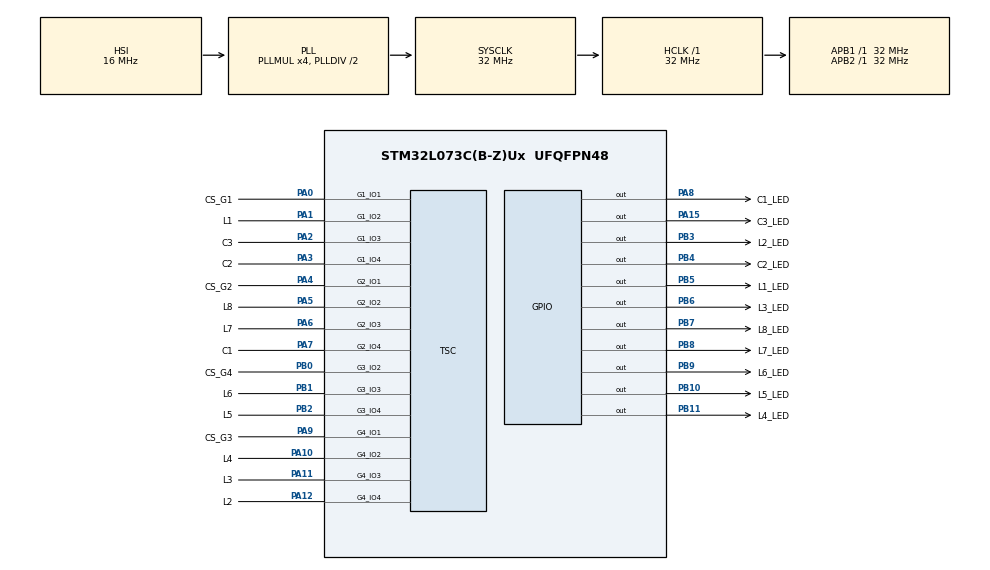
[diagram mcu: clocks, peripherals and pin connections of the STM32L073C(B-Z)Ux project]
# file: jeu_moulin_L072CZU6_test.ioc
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Mcu.Family=STM32L0
Mcu.Name=STM32L073C(B-Z)Ux
Mcu.Package=UFQFPN48
PA0.GPIO_Label=CS_G1
PA0.Mode=G1_IO1-Sampling
PA0.Signal=TSC_G1_IO1
PA1.GPIO_Label=L1
PA1.Mode=G1_IO2-Channel
PA1.Signal=TSC_G1_IO2
PA10.GPIO_Label=L4
PA10.Mode=G4_IO2-Channel
PA10.Signal=TSC_G4_IO2
PA11.GPIO_Label=L3
PA11.Mode=G4_IO3-Channel
PA11.Signal=TSC_G4_IO3
PA12.GPIO_Label=L2
PA12.Mode=G4_IO4-Channel
PA12.Signal=TSC_G4_IO4
PA13.Mode=Serial_Wire
PA13.Signal=SYS_SWDIO
PA14.Mode=Serial_Wire
PA14.Signal=SYS_SWCLK
PA15.GPIO_Label=C3_LED
PA15.Signal=GPIO_Output
PA2.GPIO_Label=C3
PA2.Mode=G1_IO3-Channel
PA2.Signal=TSC_G1_IO3
PA3.GPIO_Label=C2
PA3.Mode=G1_IO4-Channel
PA3.Signal=TSC_G1_IO4
PA4.GPIO_Label=CS_G2
PA4.Mode=G2_IO1-Sampling
PA4.Signal=TSC_G2_IO1
PA5.GPIO_Label=L8
PA5.Mode=G2_IO2-Channel
PA5.Signal=TSC_G2_IO2
PA6.GPIO_Label=L7
PA6.Mode=G2_IO3-Channel
PA6.Signal=TSC_G2_IO3
PA7.GPIO_Label=C1
PA7.Mode=G2_IO4-Channel
PA7.Signal=TSC_G2_IO4
PA8.GPIO_Label=C1_LED
PA8.Signal=GPIO_Output
PA9.GPIO_Label=CS_G3
PA9.Mode=G4_IO1-Sampling
PA9.Signal=TSC_G4_IO1
PB0.GPIO_Label=CS_G4
PB0.Mode=G3_IO2-Sampling
PB0.Signal=TSC_G3_IO2
PB1.GPIO_Label=L6
PB1.Mode=G3_IO3-Channel
PB1.Signal=TSC_G3_IO3
PB10.GPIO_Label=L5_LED
PB10.Signal=GPIO_Output
PB11.GPIO_Label=L4_LED
PB11.Signal=GPIO_Output
PB2.GPIO_Label=L5
PB2.Mode=G3_IO4-Channel
PB2.Signal=TSC_G3_IO4
PB3.GPIO_Label=L2_LED
PB3.Signal=GPIO_Output
PB4.GPIO_Label=C2_LED
PB4.Signal=GPIO_Output
PB5.GPIO_Label=L1_LED
PB5.Signal=GPIO_Output
PB6.GPIO_FM6=I2C_FASTMODEPLUS_PB6
PB6.GPIO_Label=L3_LED
PB6.Signal=GPIO_Output
PB7.GPIO_FM7=I2C_FASTMODEPLUS_PB7
PB7.GPIO_Label=L8_LED
PB7.Signal=GPIO_Output
PB8.GPIO_FM8=I2C_FASTMODEPLUS_PB8
PB8.GPIO_Label=L7_LED
PB8.Signal=GPIO_Output
PB9.GPIO_FM9=I2C_FASTMODEPLUS_PB9
PB9.GPIO_Label=L6_LED
PB9.Signal=GPIO_Output
ProjectManager.HeapSize=0x200
ProjectManager.StackSize=0x400
ProjectManager.TargetToolchain=STM32CubeIDE
RCC.AHBFreq_Value=32000000
RCC.APB1Freq_Value=32000000
RCC.APB1TimFreq_Value=32000000
RCC.APB2Freq_Value=32000000
RCC.APB2TimFreq_Value=32000000
RCC.HCLKFreq_Value=32000000
RCC.HSE_VALUE=8000000
RCC.HSI16_VALUE=16000000
RCC.HSI48_VALUE=48000000
RCC.HSI_VALUE=16000000
RCC.LSE_VALUE=32768
RCC.MSI_VALUE=2097000
RCC.PLLMUL=RCC_PLLMUL_4
RCC.SYSCLKFreq_VALUE=32000000
RCC.SYSCLKSource=RCC_SYSCLKSOURCE_PLLCLK
RCC.VCOOutputFreq_Value=64000000
TOUCHSENSING.IO_TOUCHKEY1=G1_IO2
TOUCHSENSING.IO_TOUCHKEY1-TouchSensing_Enabled=G1_IO2
TOUCHSENSING.IO_TOUCHKEY10=G2_IO4
TOUCHSENSING.IO_TOUCHKEY11=G4_IO4
TOUCHSENSING.IO_TOUCHKEY2=G2_IO2
TOUCHSENSING.IO_TOUCHKEY3=G3_IO3
TOUCHSENSING.IO_TOUCHKEY4=G4_IO2
TOUCHSENSING.IO_TOUCHKEY5=G1_IO3
TOUCHSENSING.IO_TOUCHKEY6=G2_IO3
TOUCHSENSING.IO_TOUCHKEY7=G3_IO4
TOUCHSENSING.IO_TOUCHKEY8=G4_IO3
TOUCHSENSING.IO_TOUCHKEY9=G1_IO4
TOUCHSENSING.TSLPRM_DEBOUNCE_CALIB=20
TOUCHSENSING.TSLPRM_DEBOUNCE_DETECT=4
TOUCHSENSING.TSLPRM_DEBOUNCE_ERROR=20
TOUCHSENSING.TSLPRM_DEBOUNCE_PROX=4
TOUCHSENSING.TSLPRM_DEBOUNCE_RELEASE=4
TOUCHSENSING.TSLPRM_SENSORS_DATAS=TSLPRM_TOTAL_TOUCHKEYS 3 4 4 3 
TOUCHSENSING.TSLPRM_TOTAL_TOUCHKEYS=11
TSC.CTPulseHighLength=TSC_CTPH_4CYCLES
TSC.CTPulseLowLength=TSC_CTPL_4CYCLES
TSC.ChannelIOs-G1_IO2=TSC_GROUP1_IO2
TSC.ChannelIOs-G1_IO3=TSC_GROUP1_IO3
TSC.ChannelIOs-G1_IO4=TSC_GROUP1_IO4
TSC.ChannelIOs-G2_IO2=TSC_GROUP2_IO2
TSC.ChannelIOs-G2_IO3=TSC_GROUP2_IO3
TSC.ChannelIOs-G2_IO4=TSC_GROUP2_IO4
TSC.ChannelIOs-G3_IO3=TSC_GROUP3_IO3
TSC.ChannelIOs-G3_IO4=TSC_GROUP3_IO4
TSC.ChannelIOs-G4_IO2=TSC_GROUP4_IO2
TSC.ChannelIOs-G4_IO3=TSC_GROUP4_IO3
TSC.ChannelIOs-G4_IO4=TSC_GROUP4_IO4
TSC.SamplingIOs-G1_IO1=TSC_GROUP1_IO1
TSC.SamplingIOs-G2_IO1=TSC_GROUP2_IO1
TSC.SamplingIOs-G3_IO2=TSC_GROUP3_IO2
TSC.SamplingIOs-G4_IO1=TSC_GROUP4_IO1
VP_TOUCHSENSING_VS_TOUCHSENSING.Mode=TouchSensing_Enabled
board=custom

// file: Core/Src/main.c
/* USER CODE BEGIN Header */
/**
  ******************************************************************************
  * @file           : main.c
  * @brief          : Main program body
  ******************************************************************************
  * @attention
  *
  * Copyright (c) 2025 STMicroelectronics.
  * All rights reserved.
  *
  * This software is licensed under terms that can be found in the LICENSE file
  * in the root directory of this software component.
  * If no LICENSE file comes with this software, it is provided AS-IS.
  *
  ******************************************************************************
  */
/* USER CODE END Header */
#include "main.h"
#include "touchsensing.h"

/* USER CODE BEGIN PD */
#define TKEY_DET(NB) (MyTKeys[(NB)].p_Data->StateId == TSL_STATEID_DETECT)
#define TKEY_PRX(NB) (MyTKeys[(NB)].p_Data->StateId == TSL_STATEID_PROX)
#define TKEY_REL(NB) (MyTKeys[(NB)].p_Data->StateId == TSL_STATEID_RELEASE)
#define TKEY_CAL(NB) (MyTKeys[(NB)].p_Data->StateId == TSL_STATEID_CALIB)

#define P1 1
#define P2 2
#define P3 3
#define P4 4
#define P5 5
#define P6 6
#define P7 7
#define P8 8
#define P9 9
#define P10 10
#define P11 11
#define P12 12
#define P13 13
#define P14 14
#define P15 15
#define P16 16
#define P17 17
#define P18 18
#define P19 19
#define P20 20
#define P21 21
#define P22 22
#define P23 23
#define P24 24

//define des couleurs
#define RED 1
#define GRN 2
#define OFF 0

//define pour les modes de pins
#define OUTMODE 0x10
#define INMODE 0x20

//define pour les groupe des I/O des LEDs
#define C1_G GPIOA
#define C2_G GPIOB
#define C3_G GPIOA

#define L1_G GPIOB
#define L2_G GPIOB
#define L3_G GPIOB
#define L4_G GPIOB
#define L5_G GPIOB
#define L6_G GPIOB
#define L7_G GPIOB
#define L8_G GPIOB

//define pour les nombre des pins des LEDs
#define C1 8
#define C2 4
#define C3 15

#define L1 5
#define L2 3
#define L3 6
#define L4 11
#define L5 10
#define L6 9
#define L7 8
#define L8 7
/* USER CODE END PD */

TSC_HandleTypeDef htsc;

/* USER CODE BEGIN PV */
tsl_user_status_t tsl_status;
uint16_t i, j;
uint8_t touchDetect[13];	  //correspond aux designateurs du PCB, [0] n'est pas utiliser
uint8_t prevTouchDetect[13];   //correspond à l'ancien état du tableau
uint8_t fieldState[13] = {0}; //correspond aux tableau du terrain contenant les positions
uint8_t touchPressMem[18];    //correspond à la mémoire des touches pressées la case [0] n'est pas utilisé parce que ??
uint8_t memIncrease = 0; 	  //correspond à la variable utile pour monter de cases mémoire
uint8_t btnPressed;			  //correspond à la valeur du bouton pressé de 0 à 11
uint8_t tour = RED;       	  //correspond au tour actuel, sois au rouges, sois au vert
/* USER CODE END PV */

void SystemClock_Config(void);
static void MX_GPIO_Init(void);
static void MX_TSC_Init(void);
/* USER CODE BEGIN PFP */
void LEDP(char IdLed, char color);
void LED_MODE(char pin, GPIO_TypeDef *group, char mode);
void LED_OFF(void);
void LED_Field(uint8_t array[13]);
/* USER CODE END PFP */

int main(void)
{

  /* MCU Configuration--------------------------------------------------------*/

  /* Reset of all peripherals, Initializes the Flash interface and the Systick. */
  HAL_Init();

  /* Configure the system clock */
  SystemClock_Config();

  /* Initialize all configured peripherals */
  MX_GPIO_Init();
  MX_TSC_Init();
  MX_TOUCHSENSING_Init();

  /* Infinite loop */
  /* USER CODE BEGIN WHILE */
  while (1)
  {
		if (tsl_user_Exec_IT() != TSL_USER_STATUS_BUSY) {
			int id;
			for (id = 0; id < TSLPRM_TOTAL_CHANNELS; id++) {
				if (!TKEY_CAL(id)) {
					/*   printf("Sensor%d: Delta %3d Ref %3d Measurement %3d StateId %3d\n"
					 ,id
					 ,MyTKeys[id].p_ChD->Delta
					 ,MyTKeys[id].p_ChD->Ref
					 ,MyTKeys[id].p_ChD->Meas
					 ,MyTKeys[id].p_Data->StateId);*/
					if (TKEY_DET(3) && (TKEY_DET(6))) {
						touchDetect[1] = 1;
					}		//(TKEY_DET(id))// we detect a touch
					else if (TKEY_REL(3) && (TKEY_REL(6))) {
						touchDetect[1] = 0;
					}	//(TKEY_REL(id)) // No more detection

					if (TKEY_DET(3) && (TKEY_DET(7))) {
						touchDetect[2] = 1;
					} else if (TKEY_REL(3) && (TKEY_REL(7))) {
						touchDetect[2] = 0;
					}

					if (TKEY_DET(3) && (TKEY_DET(2))) {
						touchDetect[3] = 1;
					} else if (TKEY_REL(3) && (TKEY_REL(2))) {
						touchDetect[3] = 0;
					}

					if (TKEY_DET(1) && (TKEY_DET(6))) {
						touchDetect[4] = 1;
					} else if (TKEY_REL(1) && (TKEY_REL(6))) {
						touchDetect[4] = 0;
					}

					if (TKEY_DET(1) && (TKEY_DET(7))) {
						touchDetect[5] = 1;
					} else if (TKEY_REL(1) && (TKEY_REL(7))) {
						touchDetect[5] = 0;
					}

					if (TKEY_DET(1) && (TKEY_DET(2))) {
						touchDetect[6] = 1;
					} else if (TKEY_REL(1) && (TKEY_REL(2))) {
						touchDetect[6] = 0;
					}

					if (TKEY_DET(0) && (TKEY_DET(6))) {
						touchDetect[7] = 1;
					} else if (TKEY_REL(0) && (TKEY_REL(6))) {
						touchDetect[7] = 0;
					}

					if (TKEY_DET(0) && (TKEY_DET(7))) {
						touchDetect[8] = 1;
					} else if (TKEY_REL(0) && (TKEY_REL(7))) {
						touchDetect[8] = 0;
					}

					if (TKEY_DET(0) && (TKEY_DET(2))) {
						touchDetect[9] = 1;
					} else if (TKEY_REL(0) && (TKEY_REL(2))) {
						touchDetect[9] = 0;
					}

					if (TKEY_DET(8) && (TKEY_DET(6))) {
						touchDetect[10] = 1;
					} else if (TKEY_REL(8) && (TKEY_REL(6))) {
						touchDetect[10] = 0;
					}

					if (TKEY_DET(8) && (TKEY_DET(7))) {
						touchDetect[11] = 1;
					} else if (TKEY_REL(8) && (TKEY_REL(7))) {
						touchDetect[11] = 0;
					}

					if (TKEY_DET(8) && (TKEY_DET(2))) {
						touchDetect[12] = 1;
					} else if (TKEY_REL(8) && (TKEY_REL(2))) {
						touchDetect[12] = 0;
					}
				}
			}
		} else {
			HAL_Delay(1); //Can be replace by __WFI()
		}
		//début des contrôles pour les LEDs
		//quand la détection est terminée passse dans tous le tableau
		for (int i = 0; i < sizeof(touchDetect); i++) {
			//test si le tableau de fin de détection est le même que celui de l'ancienne détection pour savoir si un flanc a changer d'état
			if (prevTouchDetect[i] == 0 && touchDetect[i] == 1) {
				//flanc détecté
				//test si le tableau à l'addresse i égal 1
				if (touchDetect[i] == 1) {
					//if(btnPressed != i){memIncrease++;}
					btnPressed = i; // Return the index of the first occurrence of 1
				}
					memIncrease++;
					touchPressMem[memIncrease] = btnPressed;
					//of the LED is RED turn it off
					if(fieldState[i] == RED){
						fieldState[btnPressed] = OFF;
					}
					//if it isnt, just change the colour according to the turn
					else{
					fieldState[btnPressed] = tour;
					//progresses the turn
						switch (tour){
						case RED :
							tour = GRN;
							break;
						case GRN :
							tour = RED;
							break;
						case OFF :
							tour = RED;
							break;
						}
					}
				//resets the memory emplacement to 0 when overflow happens
				if(memIncrease >= 18)
				{
					memIncrease = 0;
				}
			}
		prevTouchDetect[i] = touchDetect[i];
		}
		//fonction qui affiche l'état de toutes les position
		LED_Field(fieldState);
    /* USER CODE END WHILE */

  }
}

void SystemClock_Config(void)
{
  RCC_OscInitTypeDef RCC_OscInitStruct = {0};
  RCC_ClkInitTypeDef RCC_ClkInitStruct = {0};

  /** Configure the main internal regulator output voltage
  */
  __HAL_PWR_VOLTAGESCALING_CONFIG(PWR_REGULATOR_VOLTAGE_SCALE1);

  /** Initializes the RCC Oscillators according to the specified parameters
  * in the RCC_OscInitTypeDef structure.
  */
  RCC_OscInitStruct.OscillatorType = RCC_OSCILLATORTYPE_HSI;
  RCC_OscInitStruct.HSIState = RCC_HSI_ON;
  RCC_OscInitStruct.HSICalibrationValue = RCC_HSICALIBRATION_DEFAULT;
  RCC_OscInitStruct.PLL.PLLState = RCC_PLL_ON;
  RCC_OscInitStruct.PLL.PLLSource = RCC_PLLSOURCE_HSI;
  RCC_OscInitStruct.PLL.PLLMUL = RCC_PLLMUL_4;
  RCC_OscInitStruct.PLL.PLLDIV = RCC_PLLDIV_2;
  if (HAL_RCC_OscConfig(&RCC_OscInitStruct) != HAL_OK)
  {
    Error_Handler();
  }

  /** Initializes the CPU, AHB and APB buses clocks
  */
  RCC_ClkInitStruct.ClockType = RCC_CLOCKTYPE_HCLK|RCC_CLOCKTYPE_SYSCLK
                              |RCC_CLOCKTYPE_PCLK1|RCC_CLOCKTYPE_PCLK2;
  RCC_ClkInitStruct.SYSCLKSource = RCC_SYSCLKSOURCE_PLLCLK;
  RCC_ClkInitStruct.AHBCLKDivider = RCC_SYSCLK_DIV1;
  RCC_ClkInitStruct.APB1CLKDivider = RCC_HCLK_DIV1;
  RCC_ClkInitStruct.APB2CLKDivider = RCC_HCLK_DIV1;

  if (HAL_RCC_ClockConfig(&RCC_ClkInitStruct, FLASH_LATENCY_1) != HAL_OK)
  {
    Error_Handler();
  }
}

static void MX_TSC_Init(void)
{

  /** Configure the TSC peripheral
  */
  htsc.Instance = TSC;
  htsc.Init.CTPulseHighLength = TSC_CTPH_4CYCLES;
  htsc.Init.CTPulseLowLength = TSC_CTPL_4CYCLES;
  htsc.Init.SpreadSpectrum = DISABLE;
  htsc.Init.SpreadSpectrumDeviation = 1;
  htsc.Init.SpreadSpectrumPrescaler = TSC_SS_PRESC_DIV1;
  htsc.Init.PulseGeneratorPrescaler = TSC_PG_PRESC_DIV4;
  htsc.Init.MaxCountValue = TSC_MCV_8191;
  htsc.Init.IODefaultMode = TSC_IODEF_OUT_PP_LOW;
  htsc.Init.SynchroPinPolarity = TSC_SYNC_POLARITY_FALLING;
  htsc.Init.AcquisitionMode = TSC_ACQ_MODE_NORMAL;
  htsc.Init.MaxCountInterrupt = DISABLE;
  htsc.Init.ChannelIOs = TSC_GROUP1_IO2|TSC_GROUP1_IO3|TSC_GROUP1_IO4|TSC_GROUP2_IO2
                    |TSC_GROUP2_IO3|TSC_GROUP2_IO4|TSC_GROUP3_IO3|TSC_GROUP3_IO4
                    |TSC_GROUP4_IO2|TSC_GROUP4_IO3|TSC_GROUP4_IO4;
  htsc.Init.ShieldIOs = 0;
  htsc.Init.SamplingIOs = TSC_GROUP1_IO1|TSC_GROUP2_IO1|TSC_GROUP3_IO2|TSC_GROUP4_IO1;
  if (HAL_TSC_Init(&htsc) != HAL_OK)
  {
    Error_Handler();
  }

}

static void MX_GPIO_Init(void)
{
  GPIO_InitTypeDef GPIO_InitStruct = {0};

  /* GPIO Ports Clock Enable */
  __HAL_RCC_GPIOA_CLK_ENABLE();
  __HAL_RCC_GPIOB_CLK_ENABLE();

  /*Configure GPIO pin Output Level */
  HAL_GPIO_WritePin(GPIOB, L5_LED_Pin|L4_LED_Pin|L2_LED_Pin|C2_LED_Pin
                          |L1_LED_Pin|L3_LED_Pin|L8_LED_Pin|L7_LED_Pin
                          |L6_LED_Pin, GPIO_PIN_RESET);

  /*Configure GPIO pin Output Level */
  HAL_GPIO_WritePin(GPIOA, C1_LED_Pin|C3_LED_Pin, GPIO_PIN_RESET);

  /*Configure GPIO pins : L5_LED_Pin L4_LED_Pin L2_LED_Pin C2_LED_Pin
                           L1_LED_Pin L3_LED_Pin L8_LED_Pin L7_LED_Pin
                           L6_LED_Pin */
  GPIO_InitStruct.Pin = L5_LED_Pin|L4_LED_Pin|L2_LED_Pin|C2_LED_Pin
                          |L1_LED_Pin|L3_LED_Pin|L8_LED_Pin|L7_LED_Pin
                          |L6_LED_Pin;
  GPIO_InitStruct.Mode = GPIO_MODE_OUTPUT_PP;
  GPIO_InitStruct.Pull = GPIO_NOPULL;
  GPIO_InitStruct.Speed = GPIO_SPEED_FREQ_LOW;
  HAL_GPIO_Init(GPIOB, &GPIO_InitStruct);

  /*Configure GPIO pins : C1_LED_Pin C3_LED_Pin */
  GPIO_InitStruct.Pin = C1_LED_Pin|C3_LED_Pin;
  GPIO_InitStruct.Mode = GPIO_MODE_OUTPUT_PP;
  GPIO_InitStruct.Pull = GPIO_NOPULL;
  GPIO_InitStruct.Speed = GPIO_SPEED_FREQ_LOW;
  HAL_GPIO_Init(GPIOA, &GPIO_InitStruct);

  /**/
  HAL_I2CEx_EnableFastModePlus(I2C_FASTMODEPLUS_PB6);

  /**/
  HAL_I2CEx_EnableFastModePlus(I2C_FASTMODEPLUS_PB7);

  /**/
  HAL_I2CEx_EnableFastModePlus(I2C_FASTMODEPLUS_PB8);

  /**/
  HAL_I2CEx_EnableFastModePlus(I2C_FASTMODEPLUS_PB9);

}

/* USER CODE BEGIN 4 */
//fonction pour allumer 1 LED
void LEDP(char IdLed, char color) {
	//change toutes les pins de colonne en output
	LED_MODE(C1, C1_G, OUTMODE);
	LED_MODE(C2, C2_G, OUTMODE);
	LED_MODE(C3, C3_G, OUTMODE);

	//la variable IdLed dit quelle led (P1-P16)
	switch (IdLed) {
	//LED1 de la ligne 1
	case P1:
		if (color == RED) {
			//changes les pins pour les colonne qu'on ne souhaite pas allumer en input
			LED_MODE(C1, C1_G, OUTMODE);
			LED_MODE(C2, C2_G, INMODE);
			LED_MODE(C3, C3_G, INMODE);

			//envoie la commande pour la LED qu'on veut allumer
			HAL_GPIO_WritePin(C1_G, C1_LED_Pin, GPIO_PIN_SET);
			HAL_GPIO_WritePin(L1_G, L1_LED_Pin, GPIO_PIN_RESET);

			//set tout les autre pin de ligne à 1 pour ne rien allumer en trop
			HAL_GPIO_WritePin(L2_G, L2_LED_Pin, GPIO_PIN_SET);
			HAL_GPIO_WritePin(L3_G, L3_LED_Pin, GPIO_PIN_SET);
			HAL_GPIO_WritePin(L4_G, L4_LED_Pin, GPIO_PIN_SET);
			HAL_GPIO_WritePin(L5_G, L5_LED_Pin, GPIO_PIN_SET);
			HAL_GPIO_WritePin(L6_G, L6_LED_Pin, GPIO_PIN_SET);
			HAL_GPIO_WritePin(L7_G, L7_LED_Pin, GPIO_PIN_SET);
			HAL_GPIO_WritePin(L8_G, L8_LED_Pin, GPIO_PIN_SET);
		}
		if (color == GRN) {
			//changes les pins pour les colonne qu'on ne souhaite pas allumer en input
			LED_MODE(C1, C1_G, OUTMODE);
			LED_MODE(C2, C2_G, INMODE);
			LED_MODE(C3, C3_G, INMODE);

			//envoie la commande pour la LED qu'on veut allumer
			HAL_GPIO_WritePin(C1_G, C1_LED_Pin, GPIO_PIN_RESET);
			HAL_GPIO_WritePin(L1_G, L1_LED_Pin, GPIO_PIN_SET);

			//set tout les autre pin de ligne à 1 pour ne rien allumer en trop
			HAL_GPIO_WritePin(L2_G, L2_LED_Pin, GPIO_PIN_RESET);
			HAL_GPIO_WritePin(L3_G, L3_LED_Pin, GPIO_PIN_RESET);
			HAL_GPIO_WritePin(L4_G, L4_LED_Pin, GPIO_PIN_RESET);
			HAL_GPIO_WritePin(L5_G, L5_LED_Pin, GPIO_PIN_RESET);
			HAL_GPIO_WritePin(L6_G, L6_LED_Pin, GPIO_PIN_RESET);
			HAL_GPIO_WritePin(L7_G, L7_LED_Pin, GPIO_PIN_RESET);
			HAL_GPIO_WritePin(L8_G, L8_LED_Pin, GPIO_PIN_RESET);
		}
		if (color == OFF) {
			//éteint la LED
			HAL_GPIO_WritePin(C1_G, C1_LED_Pin, GPIO_PIN_RESET);
			HAL_GPIO_WritePin(L1_G, L1_LED_Pin, GPIO_PIN_RESET);
		}
		break;

	//LED2 de la ligne 1
	case P2:
		if (color == RED) {
			//changes les pins pour les colonne qu'on ne souhaite pas allumer en input
			LED_MODE(C1, C1_G, INMODE);
			LED_MODE(C3, C3_G, INMODE);

			//envoie la commande pour la LED qu'on veut allumer
			HAL_GPIO_WritePin(C2_G, C2_LED_Pin, GPIO_PIN_SET);
			HAL_GPIO_WritePin(L1_G, L1_LED_Pin, GPIO_PIN_RESET);

			//set tout les autre pin de ligne à 1 pour ne rien allumer en trop
			HAL_GPIO_WritePin(L2_G, L2_LED_Pin, GPIO_PIN_SET);
			HAL_GPIO_WritePin(L3_G, L3_LED_Pin, GPIO_PIN_SET);
			HAL_GPIO_WritePin(L4_G, L4_LED_Pin, GPIO_PIN_SET);
			HAL_GPIO_WritePin(L5_G, L5_LED_Pin, GPIO_PIN_SET);
			HAL_GPIO_WritePin(L6_G, L6_LED_Pin, GPIO_PIN_SET);
			HAL_GPIO_WritePin(L7_G, L7_LED_Pin, GPIO_PIN_SET);
			HAL_GPIO_WritePin(L8_G, L8_LED_Pin, GPIO_PIN_SET);
		}
		if (color == GRN) {
			//changes les pins pour les colonne qu'on ne souhaite pas allumer en input
			LED_MODE(C1, C1_G, INMODE);
			LED_MODE(C3, C3_G, INMODE);

			//envoie la commande pour la LED qu'on veut allumer
			HAL_GPIO_WritePin(C2_G, C2_LED_Pin, GPIO_PIN_RESET);
			HAL_GPIO_WritePin(L1_G, L1_LED_Pin, GPIO_PIN_SET);

			//set tout les autre pin de ligne à 1 pour ne rien allumer en trop
			HAL_GPIO_WritePin(L2_G, L2_LED_Pin, GPIO_PIN_RESET);
			HAL_GPIO_WritePin(L3_G, L3_LED_Pin, GPIO_PIN_RESET);
			HAL_GPIO_WritePin(L4_G, L4_LED_Pin, GPIO_PIN_RESET);
			HAL_GPIO_WritePin(L5_G, L5_LED_Pin, GPIO_PIN_RESET);
			HAL_GPIO_WritePin(L6_G, L6_LED_Pin, GPIO_PIN_RESET);
			HAL_GPIO_WritePin(L7_G, L7_LED_Pin, GPIO_PIN_RESET);
			HAL_GPIO_WritePin(L8_G, L8_LED_Pin, GPIO_PIN_RESET);
		}
		if (color == OFF) {
			//éteint la LED
			HAL_GPIO_WritePin(C2_G, C2_LED_Pin, GPIO_PIN_RESET);
			HAL_GPIO_WritePin(L1_G, L1_LED_Pin, GPIO_PIN_RESET);
		}
		break;

	//LED3 de la ligne 1
	case P3:
		if (color == RED) {
			//changes les pins pour les colonne qu'on ne souhaite pas allumer en input
			LED_MODE(C1, C1_G, INMODE);
			LED_MODE(C2, C2_G, INMODE);

			//envoie la commande pour la LED qu'on veut allumer
			HAL_GPIO_WritePin(C3_G, C3_LED_Pin, GPIO_PIN_SET);
			HAL_GPIO_WritePin(L1_G, L1_LED_Pin, GPIO_PIN_RESET);

			//set tout les autre pin de ligne à 1 pour ne rien allumer en trop
			HAL_GPIO_WritePin(L2_G, L2_LED_Pin, GPIO_PIN_SET);
			HAL_GPIO_WritePin(L3_G, L3_LED_Pin, GPIO_PIN_SET);
			HAL_GPIO_WritePin(L4_G, L4_LED_Pin, GPIO_PIN_SET);
			HAL_GPIO_WritePin(L5_G, L5_LED_Pin, GPIO_PIN_SET);
			HAL_GPIO_WritePin(L6_G, L6_LED_Pin, GPIO_PIN_SET);
			HAL_GPIO_WritePin(L7_G, L7_LED_Pin, GPIO_PIN_SET);
			HAL_GPIO_WritePin(L8_G, L8_LED_Pin, GPIO_PIN_SET);
		}
		if (color == GRN) {
			//changes les pins pour les colonne qu'on ne souhaite pas allumer en input
			LED_MODE(C1, C1_G, INMODE);
			LED_MODE(C2, C2_G, INMODE);

			//envoie la commande pour la LED qu'on veut allumer
			HAL_GPIO_WritePin(C3_G, C3_LED_Pin, GPIO_PIN_RESET);
			HAL_GPIO_WritePin(L1_G, L1_LED_Pin, GPIO_PIN_SET);

			//set tout les autre pin de ligne à 1 pour ne rien allumer en trop
			HAL_GPIO_WritePin(L2_G, L2_LED_Pin, GPIO_PIN_RESET);
			HAL_GPIO_WritePin(L3_G, L3_LED_Pin, GPIO_PIN_RESET);
			HAL_GPIO_WritePin(L4_G, L4_LED_Pin, GPIO_PIN_RESET);
			HAL_GPIO_WritePin(L5_G, L5_LED_Pin, GPIO_PIN_RESET);
			HAL_GPIO_WritePin(L6_G, L6_LED_Pin, GPIO_PIN_RESET);
			HAL_GPIO_WritePin(L7_G, L7_LED_Pin, GPIO_PIN_RESET);
			HAL_GPIO_WritePin(L8_G, L8_LED_Pin, GPIO_PIN_RESET);
		}
		if (color == OFF) {
			//éteint la LED
			HAL_GPIO_WritePin(C3_G, C3_LED_Pin, GPIO_PIN_RESET);
			HAL_GPIO_WritePin(L1_G, L1_LED_Pin, GPIO_PIN_RESET);
		}
		break;

		//LED1 de la ligne 2
	case P4:
		if (color == RED) {
			//changes les pins pour les colonne qu'on ne souhaite pas allumer en input
			LED_MODE(C2, C2_G, INMODE);
			LED_MODE(C3, C3_G, INMODE);

			//envoie la commande pour la LED qu'on veut allumer
			HAL_GPIO_WritePin(C1_G, C1_LED_Pin, GPIO_PIN_SET);
			HAL_GPIO_WritePin(L2_G, L2_LED_Pin, GPIO_PIN_RESET);

			//set tout les autre pin de ligne à 1 pour ne rien allumer en trop
			HAL_GPIO_WritePin(L1_G, L1_LED_Pin, GPIO_PIN_SET);
			HAL_GPIO_WritePin(L3_G, L3_LED_Pin, GPIO_PIN_SET);
			HAL_GPIO_WritePin(L4_G, L4_LED_Pin, GPIO_PIN_SET);
			HAL_GPIO_WritePin(L5_G, L5_LED_Pin, GPIO_PIN_SET);
			HAL_GPIO_WritePin(L6_G, L6_LED_Pin, GPIO_PIN_SET);
			HAL_GPIO_WritePin(L7_G, L7_LED_Pin, GPIO_PIN_SET);
			HAL_GPIO_WritePin(L8_G, L8_LED_Pin, GPIO_PIN_SET);
		}
		if (color == GRN) {
			//changes les pins pour les colonne qu'on ne souhaite pas allumer en input
			LED_MODE(C2, C2_G, INMODE);
			LED_MODE(C3, C3_G, INMODE);

			//envoie la commande pour la LED qu'on veut allumer
			HAL_GPIO_WritePin(C1_G, C1_LED_Pin, GPIO_PIN_RESET);
			HAL_GPIO_WritePin(L2_G, L2_LED_Pin, GPIO_PIN_SET);

			//set tout les autre pin de ligne à 1 pour ne rien allumer en trop
			HAL_GPIO_WritePin(L1_G, L1_LED_Pin, GPIO_PIN_RESET);
			HAL_GPIO_WritePin(L3_G, L3_LED_Pin, GPIO_PIN_RESET);
			HAL_GPIO_WritePin(L4_G, L4_LED_Pin, GPIO_PIN_RESET);
			HAL_GPIO_WritePin(L5_G, L5_LED_Pin, GPIO_PIN_RESET);
			HAL_GPIO_WritePin(L6_G, L6_LED_Pin, GPIO_PIN_RESET);
			HAL_GPIO_WritePin(L7_G, L7_LED_Pin, GPIO_PIN_RESET);
			HAL_GPIO_WritePin(L8_G, L8_LED_Pin, GPIO_PIN_RESET);
		}
		if (color == OFF) {
			//éteint la LED
			HAL_GPIO_WritePin(C3_G, C3_LED_Pin, GPIO_PIN_RESET);
			HAL_GPIO_WritePin(L2_G, L2_LED_Pin, GPIO_PIN_RESET);
		}
		break;

	//LED2 de la ligne 2
	case P5:
		if (color == RED) {
			//changes les pins pour les colonne qu'on ne souhaite pas allumer en input
			LED_MODE(C1, C1_G, INMODE);
			LED_MODE(C3, C3_G, INMODE);

			//envoie la commande pour la LED qu'on veut allumer
			HAL_GPIO_WritePin(C2_G, C2_LED_Pin, GPIO_PIN_SET);
			HAL_GPIO_WritePin(L2_G, L2_LED_Pin, GPIO_PIN_RESET);

			//set tout les autre pin de ligne à 1 pour ne rien allumer en trop
			HAL_GPIO_WritePin(L1_G, L1_LED_Pin, GPIO_PIN_SET);
			HAL_GPIO_WritePin(L3_G, L3_LED_Pin, GPIO_PIN_SET);
			HAL_GPIO_WritePin(L4_G, L4_LED_Pin, GPIO_PIN_SET);
			HAL_GPIO_WritePin(L5_G, L5_LED_Pin, GPIO_PIN_SET);
			HAL_GPIO_WritePin(L6_G, L6_LED_Pin, GPIO_PIN_SET);
			HAL_GPIO_WritePin(L7_G, L7_LED_Pin, GPIO_PIN_SET);
			HAL_GPIO_WritePin(L8_G, L8_LED_Pin, GPIO_PIN_SET);
		}
		if (color == GRN) {
			//changes les pins pour les colonne qu'on ne souhaite pas allumer en input
			LED_MODE(C1, C1_G, INMODE);
			LED_MODE(C3, C3_G, INMODE);

			//envoie la commande pour la LED qu'on veut allumer
			HAL_GPIO_WritePin(C2_G, C2_LED_Pin, GPIO_PIN_RESET);
			HAL_GPIO_WritePin(L2_G, L2_LED_Pin, GPIO_PIN_SET);

			//set tout les autre pin de ligne à 1 pour ne rien allumer en trop
			HAL_GPIO_WritePin(L1_G, L1_LED_Pin, GPIO_PIN_RESET);
			HAL_GPIO_WritePin(L3_G, L3_LED_Pin, GPIO_PIN_RESET);
			HAL_GPIO_WritePin(L4_G, L4_LED_Pin, GPIO_PIN_RESET);
			HAL_GPIO_WritePin(L5_G, L5_LED_Pin, GPIO_PIN_RESET);
			HAL_GPIO_WritePin(L6_G, L6_LED_Pin, GPIO_PIN_RESET);
			HAL_GPIO_WritePin(L7_G, L7_LED_Pin, GPIO_PIN_RESET);
			HAL_GPIO_WritePin(L8_G, L8_LED_Pin, GPIO_PIN_RESET);
		}
		if (color == OFF) {
			//éteint la LED
			HAL_GPIO_WritePin(C2_G, C2_LED_Pin, GPIO_PIN_RESET);
			HAL_GPIO_WritePin(L2_G, L2_LED_Pin, GPIO_PIN_RESET);
		}
		break;

	//LED3 de la ligne 2
	case P6:
		if (color == RED) {
			//changes les pins pour les colonne qu'on ne souhaite pas allumer en input
			LED_MODE(C1, C1_G, INMODE);
			LED_MODE(C2, C2_G, INMODE);

			//envoie la commande pour la LED qu'on veut allumer
			HAL_GPIO_WritePin(C3_G, C3_LED_Pin, GPIO_PIN_SET);
			HAL_GPIO_WritePin(L2_G, L2_LED_Pin, GPIO_PIN_RESET);

			//set tout les autre pin de ligne à 1 pour ne rien allumer en trop
			HAL_GPIO_WritePin(L1_G, L1_LED_Pin, GPIO_PIN_SET);
			HAL_GPIO_WritePin(L3_G, L3_LED_Pin, GPIO_PIN_SET);
			HAL_GPIO_WritePin(L4_G, L4_LED_Pin, GPIO_PIN_SET);
			HAL_GPIO_WritePin(L5_G, L5_LED_Pin, GPIO_PIN_SET);
			HAL_GPIO_WritePin(L6_G, L6_LED_Pin, GPIO_PIN_SET);
			HAL_GPIO_WritePin(L7_G, L7_LED_Pin, GPIO_PIN_SET);
			HAL_GPIO_WritePin(L8_G, L8_LED_Pin, GPIO_PIN_SET);
		}
		if (color == GRN) {
			//changes les pins pour les colonne qu'on ne souhaite pas allumer en input
			LED_MODE(C1, C1_G, INMODE);
			LED_MODE(C2, C2_G, INMODE);

			//envoie la commande pour la LED qu'on veut allumer
			HAL_GPIO_WritePin(C3_G, C3_LED_Pin, GPIO_PIN_RESET);
			HAL_GPIO_WritePin(L2_G, L2_LED_Pin, GPIO_PIN_SET);

			//set tout les autre pin de ligne à 1 pour ne rien allumer en trop
			HAL_GPIO_WritePin(L1_G, L1_LED_Pin, GPIO_PIN_RESET);
			HAL_GPIO_WritePin(L3_G, L3_LED_Pin, GPIO_PIN_RESET);
			HAL_GPIO_WritePin(L4_G, L4_LED_Pin, GPIO_PIN_RESET);
			HAL_GPIO_WritePin(L5_G, L5_LED_Pin, GPIO_PIN_RESET);
			HAL_GPIO_WritePin(L6_G, L6_LED_Pin, GPIO_PIN_RESET);
			HAL_GPIO_WritePin(L7_G, L7_LED_Pin, GPIO_PIN_RESET);
			HAL_GPIO_WritePin(L8_G, L8_LED_Pin, GPIO_PIN_RESET);
		}
		if (color == OFF) {
			//éteint la LED
			HAL_GPIO_WritePin(C3_G, C3_LED_Pin, GPIO_PIN_RESET);
			HAL_GPIO_WritePin(L2_G, L2_LED_Pin, GPIO_PIN_RESET);
		}
		break;

		//LED1 de la ligne 3
	case P7:
		if (color == RED) {
			//changes les pins pour les colonne qu'on ne souhaite pas allumer en input
			LED_MODE(C2, C2_G, INMODE);
			LED_MODE(C3, C3_G, INMODE);

			//envoie la commande pour la LED qu'on veut allumer
			HAL_GPIO_WritePin(C1_G, C1_LED_Pin, GPIO_PIN_SET);
			HAL_GPIO_WritePin(L3_G, L3_LED_Pin, GPIO_PIN_RESET);

			//set tout les autre pin de ligne à 1 pour ne rien allumer en trop
			HAL_GPIO_WritePin(L1_G, L1_LED_Pin, GPIO_PIN_SET);
			HAL_GPIO_WritePin(L2_G, L2_LED_Pin, GPIO_PIN_SET);
			HAL_GPIO_WritePin(L4_G, L4_LED_Pin, GPIO_PIN_SET);
			HAL_GPIO_WritePin(L5_G, L5_LED_Pin, GPIO_PIN_SET);
			HAL_GPIO_WritePin(L6_G, L6_LED_Pin, GPIO_PIN_SET);
			HAL_GPIO_WritePin(L7_G, L7_LED_Pin, GPIO_PIN_SET);
			HAL_GPIO_WritePin(L8_G, L8_LED_Pin, GPIO_PIN_SET);
		}
		if (color == GRN) {
			//changes les pins pour les colonne qu'on ne souhaite pas allumer en input
			LED_MODE(C2, C2_G, INMODE);
			LED_MODE(C3, C3_G, INMODE);

			//envoie la commande pour la LED qu'on veut allumer
			HAL_GPIO_WritePin(C1_G, C1_LED_Pin, GPIO_PIN_RESET);
			HAL_GPIO_WritePin(L3_G, L3_LED_Pin, GPIO_PIN_SET);

			//set tout les autre pin de ligne à 1 pour ne rien allumer en trop
			HAL_GPIO_WritePin(L1_G, L1_LED_Pin, GPIO_PIN_RESET);
			HAL_GPIO_WritePin(L2_G, L2_LED_Pin, GPIO_PIN_RESET);
			HAL_GPIO_WritePin(L4_G, L4_LED_Pin, GPIO_PIN_RESET);
			HAL_GPIO_WritePin(L5_G, L5_LED_Pin, GPIO_PIN_RESET);
			HAL_GPIO_WritePin(L6_G, L6_LED_Pin, GPIO_PIN_RESET);
			HAL_GPIO_WritePin(L7_G, L7_LED_Pin, GPIO_PIN_RESET);
			HAL_GPIO_WritePin(L8_G, L8_LED_Pin, GPIO_PIN_RESET);
		}
		if (color == OFF) {
			//éteint la LED
			HAL_GPIO_WritePin(C3_G, C3_LED_Pin, GPIO_PIN_RESET);
			HAL_GPIO_WritePin(L3_G, L3_LED_Pin, GPIO_PIN_RESET);
		}
		break;

	//LED2 de la ligne 3
	case P8:
		if (color == RED) {
			//changes les pins pour les colonne qu'on ne souhaite pas allumer en input
			LED_MODE(C1, C1_G, INMODE);
			LED_MODE(C3, C3_G, INMODE);

			//envoie la commande pour la LED qu'on veut allumer
			HAL_GPIO_WritePin(C2_G, C2_LED_Pin, GPIO_PIN_SET);
			HAL_GPIO_WritePin(L3_G, L3_LED_Pin, GPIO_PIN_RESET);

			//set tout les autre pin de ligne à 1 pour ne rien allumer en trop
			HAL_GPIO_WritePin(L1_G, L1_LED_Pin, GPIO_PIN_SET);
			HAL_GPIO_WritePin(L2_G, L2_LED_Pin, GPIO_PIN_SET);
			HAL_GPIO_WritePin(L4_G, L4_LED_Pin, GPIO_PIN_SET);
			HAL_GPIO_WritePin(L5_G, L5_LED_Pin, GPIO_PIN_SET);
			HAL_GPIO_WritePin(L6_G, L6_LED_Pin, GPIO_PIN_SET);
			HAL_GPIO_WritePin(L7_G, L7_LED_Pin, GPIO_PIN_SET);
			HAL_GPIO_WritePin(L8_G, L8_LED_Pin, GPIO_PIN_SET);
		}
		if (color == GRN) {
			//changes les pins pour les colonne qu'on ne souhaite pas allumer en input
			LED_MODE(C1, C1_G, INMODE);
			LED_MODE(C3, C3_G, INMODE);

			//envoie la commande pour la LED qu'on veut allumer
			HAL_GPIO_WritePin(C2_G, C2_LED_Pin, GPIO_PIN_RESET);
			HAL_GPIO_WritePin(L3_G, L3_LED_Pin, GPIO_PIN_SET);

			//set tout les autre pin de ligne à 1 pour ne rien allumer en trop
			HAL_GPIO_WritePin(L1_G, L1_LED_Pin, GPIO_PIN_RESET);
			HAL_GPIO_WritePin(L2_G, L2_LED_Pin, GPIO_PIN_RESET);
			HAL_GPIO_WritePin(L4_G, L4_LED_Pin, GPIO_PIN_RESET);
			HAL_GPIO_WritePin(L5_G, L5_LED_Pin, GPIO_PIN_RESET);
			HAL_GPIO_WritePin(L6_G, L6_LED_Pin, GPIO_PIN_RESET);
			HAL_GPIO_WritePin(L7_G, L7_LED_Pin, GPIO_PIN_RESET);
			HAL_GPIO_WritePin(L8_G, L8_LED_Pin, GPIO_PIN_RESET);
		}
		if (color == OFF) {
			//éteint la LED
			HAL_GPIO_WritePin(C2_G, C2_LED_Pin, GPIO_PIN_RESET);
			HAL_GPIO_WritePin(L3_G, L3_LED_Pin, GPIO_PIN_RESET);
		}
		break;

	//LED3 de la ligne 3
	case P9:
		if (color == RED) {
			//changes les pins pour les colonne qu'on ne souhaite pas allumer en input
			LED_MODE(C1, C1_G, INMODE);
			LED_MODE(C2, C2_G, INMODE);

			//envoie la commande pour la LED qu'on veut allumer
			HAL_GPIO_WritePin(C3_G, C3_LED_Pin, GPIO_PIN_SET);
			HAL_GPIO_WritePin(L3_G, L3_LED_Pin, GPIO_PIN_RESET);

			//set tout les autre pin de ligne à 1 pour ne rien allumer en trop
			HAL_GPIO_WritePin(L1_G, L1_LED_Pin, GPIO_PIN_SET);
			HAL_GPIO_WritePin(L2_G, L2_LED_Pin, GPIO_PIN_SET);
			HAL_GPIO_WritePin(L4_G, L4_LED_Pin, GPIO_PIN_SET);
			HAL_GPIO_WritePin(L5_G, L5_LED_Pin, GPIO_PIN_SET);
			HAL_GPIO_WritePin(L6_G, L6_LED_Pin, GPIO_PIN_SET);
			HAL_GPIO_WritePin(L7_G, L7_LED_Pin, GPIO_PIN_SET);
			HAL_GPIO_WritePin(L8_G, L8_LED_Pin, GPIO_PIN_SET);
		}
		if (color == GRN) {
			//changes les pins pour les colonne qu'on ne souhaite pas allumer en input
			LED_MODE(C1, C1_G, INMODE);
			LED_MODE(C2, C2_G, INMODE);

			//envoie la commande pour la LED qu'on veut allumer
			HAL_GPIO_WritePin(C3_G, C3_LED_Pin, GPIO_PIN_RESET);
			HAL_GPIO_WritePin(L3_G, L3_LED_Pin, GPIO_PIN_SET);

			//set tout les autre pin de ligne à 1 pour ne rien allumer en trop
			HAL_GPIO_WritePin(L1_G, L1_LED_Pin, GPIO_PIN_RESET);
			HAL_GPIO_WritePin(L2_G, L2_LED_Pin, GPIO_PIN_RESET);
			HAL_GPIO_WritePin(L4_G, L4_LED_Pin, GPIO_PIN_RESET);
			HAL_GPIO_WritePin(L5_G, L5_LED_Pin, GPIO_PIN_RESET);
			HAL_GPIO_WritePin(L6_G, L6_LED_Pin, GPIO_PIN_RESET);
			HAL_GPIO_WritePin(L7_G, L7_LED_Pin, GPIO_PIN_RESET);
			HAL_GPIO_WritePin(L8_G, L8_LED_Pin, GPIO_PIN_RESET);
		}
		if (color == OFF) {
			//éteint la LED
			HAL_GPIO_WritePin(C3_G, C3_LED_Pin, GPIO_PIN_RESET);
			HAL_GPIO_WritePin(L3_G, L3_LED_Pin, GPIO_PIN_RESET);
		}
		break;

		//LED1 de la ligne 4
	case P10:
		if (color == RED) {
			//changes les pins pour les colonne qu'on ne souhaite pas allumer en input
			LED_MODE(C2, C2_G, INMODE);
			LED_MODE(C3, C3_G, INMODE);

			//envoie la commande pour la LED qu'on veut allumer
			HAL_GPIO_WritePin(C1_G, C1_LED_Pin, GPIO_PIN_SET);
			HAL_GPIO_WritePin(L4_G, L4_LED_Pin, GPIO_PIN_RESET);

			//set tout les autre pin de ligne à 1 pour ne rien allumer en trop
			HAL_GPIO_WritePin(L1_G, L1_LED_Pin, GPIO_PIN_SET);
			HAL_GPIO_WritePin(L2_G, L2_LED_Pin, GPIO_PIN_SET);
			HAL_GPIO_WritePin(L3_G, L3_LED_Pin, GPIO_PIN_SET);
			HAL_GPIO_WritePin(L5_G, L5_LED_Pin, GPIO_PIN_SET);
			HAL_GPIO_WritePin(L6_G, L6_LED_Pin, GPIO_PIN_SET);
			HAL_GPIO_WritePin(L7_G, L7_LED_Pin, GPIO_PIN_SET);
			HAL_GPIO_WritePin(L8_G, L8_LED_Pin, GPIO_PIN_SET);
		}
		if (color == GRN) {
			//changes les pins pour les colonne qu'on ne souhaite pas allumer en input
			LED_MODE(C2, C2_G, INMODE);
			LED_MODE(C3, C3_G, INMODE);

			//envoie la commande pour la LED qu'on veut allumer
			HAL_GPIO_WritePin(C1_G, C1_LED_Pin, GPIO_PIN_RESET);
			HAL_GPIO_WritePin(L4_G, L4_LED_Pin, GPIO_PIN_SET);

			//set tout les autre pin de ligne à 1 pour ne rien allumer en trop
			HAL_GPIO_WritePin(L1_G, L1_LED_Pin, GPIO_PIN_RESET);
			HAL_GPIO_WritePin(L2_G, L2_LED_Pin, GPIO_PIN_RESET);
			HAL_GPIO_WritePin(L3_G, L3_LED_Pin, GPIO_PIN_RESET);
			HAL_GPIO_WritePin(L5_G, L5_LED_Pin, GPIO_PIN_RESET);
			HAL_GPIO_WritePin(L6_G, L6_LED_Pin, GPIO_PIN_RESET);
			HAL_GPIO_WritePin(L7_G, L7_LED_Pin, GPIO_PIN_RESET);
			HAL_GPIO_WritePin(L8_G, L8_LED_Pin, GPIO_PIN_RESET);
		}
		if (color == OFF) {
			//éteint la LED
			HAL_GPIO_WritePin(C3_G, C3_LED_Pin, GPIO_PIN_RESET);
			HAL_GPIO_WritePin(L4_G, L4_LED_Pin, GPIO_PIN_RESET);
		}
		break;

	//LED2 de la ligne 4
	case P11:
		if (color == RED) {
			//changes les pins pour les colonne qu'on ne souhaite pas allumer en input
			LED_MODE(C1, C1_G, INMODE);
			LED_MODE(C3, C3_G, INMODE);

			//envoie la commande pour la LED qu'on veut allumer
			HAL_GPIO_WritePin(C2_G, C2_LED_Pin, GPIO_PIN_SET);
			HAL_GPIO_WritePin(L4_G, L4_LED_Pin, GPIO_PIN_RESET);

			//set tout les autre pin de ligne à 1 pour ne rien allumer en trop
			HAL_GPIO_WritePin(L1_G, L1_LED_Pin, GPIO_PIN_SET);
			HAL_GPIO_WritePin(L2_G, L2_LED_Pin, GPIO_PIN_SET);
			HAL_GPIO_WritePin(L3_G, L3_LED_Pin, GPIO_PIN_SET);
			HAL_GPIO_WritePin(L5_G, L5_LED_Pin, GPIO_PIN_SET);
			HAL_GPIO_WritePin(L6_G, L6_LED_Pin, GPIO_PIN_SET);
			HAL_GPIO_WritePin(L7_G, L7_LED_Pin, GPIO_PIN_SET);
			HAL_GPIO_WritePin(L8_G, L8_LED_Pin, GPIO_PIN_SET);
		}
		if (color == GRN) {
			//changes les pins pour les colonne qu'on ne souhaite pas allumer en input
			LED_MODE(C1, C1_G, INMODE);
			LED_MODE(C3, C3_G, INMODE);

			//envoie la commande pour la LED qu'on veut allumer
			HAL_GPIO_WritePin(C2_G, C2_LED_Pin, GPIO_PIN_RESET);
			HAL_GPIO_WritePin(L4_G, L4_LED_Pin, GPIO_PIN_SET);

			//set tout les autre pin de ligne à 1 pour ne rien allumer en trop
			HAL_GPIO_WritePin(L1_G, L1_LED_Pin, GPIO_PIN_RESET);
			HAL_GPIO_WritePin(L2_G, L2_LED_Pin, GPIO_PIN_RESET);
			HAL_GPIO_WritePin(L3_G, L3_LED_Pin, GPIO_PIN_RESET);
			HAL_GPIO_WritePin(L5_G, L5_LED_Pin, GPIO_PIN_RESET);
			HAL_GPIO_WritePin(L6_G, L6_LED_Pin, GPIO_PIN_RESET);
			HAL_GPIO_WritePin(L7_G, L7_LED_Pin, GPIO_PIN_RESET);
			HAL_GPIO_WritePin(L8_G, L8_LED_Pin, GPIO_PIN_RESET);
		}
		if (color == OFF) {
			//éteint la LED
			HAL_GPIO_WritePin(C2_G, C2_LED_Pin, GPIO_PIN_RESET);
			HAL_GPIO_WritePin(L4_G, L4_LED_Pin, GPIO_PIN_RESET);
		}
		break;

	//LED3 de la ligne 4
	case P12:
		if (color == RED) {
			//changes les pins pour les colonne qu'on ne souhaite pas allumer en input
			LED_MODE(C1, C1_G, INMODE);
			LED_MODE(C2, C2_G, INMODE);

			//envoie la commande pour la LED qu'on veut allumer
			HAL_GPIO_WritePin(C3_G, C3_LED_Pin, GPIO_PIN_SET);
			HAL_GPIO_WritePin(L4_G, L4_LED_Pin, GPIO_PIN_RESET);

			//set tout les autre pin de ligne à 1 pour ne rien allumer en trop
			HAL_GPIO_WritePin(L1_G, L1_LED_Pin, GPIO_PIN_SET);
			HAL_GPIO_WritePin(L2_G, L2_LED_Pin, GPIO_PIN_SET);
			HAL_GPIO_WritePin(L3_G, L3_LED_Pin, GPIO_PIN_SET);
			HAL_GPIO_WritePin(L5_G, L5_LED_Pin, GPIO_PIN_SET);
			HAL_GPIO_WritePin(L6_G, L6_LED_Pin, GPIO_PIN_SET);
			HAL_GPIO_WritePin(L7_G, L7_LED_Pin, GPIO_PIN_SET);
			HAL_GPIO_WritePin(L8_G, L8_LED_Pin, GPIO_PIN_SET);
		}
		if (color == GRN) {
			//changes les pins pour les colonne qu'on ne souhaite pas allumer en input
			LED_MODE(C1, C1_G, INMODE);
			LED_MODE(C2, C2_G, INMODE);

			//envoie la commande pour la LED qu'on veut allumer
			HAL_GPIO_WritePin(C3_G, C3_LED_Pin, GPIO_PIN_RESET);
			HAL_GPIO_WritePin(L4_G, L4_LED_Pin, GPIO_PIN_SET);

			//set tout les autre pin de ligne à 1 pour ne rien allumer en trop
			HAL_GPIO_WritePin(L1_G, L1_LED_Pin, GPIO_PIN_RESET);
			HAL_GPIO_WritePin(L2_G, L2_LED_Pin, GPIO_PIN_RESET);
			HAL_GPIO_WritePin(L3_G, L3_LED_Pin, GPIO_PIN_RESET);
			HAL_GPIO_WritePin(L5_G, L5_LED_Pin, GPIO_PIN_RESET);
			HAL_GPIO_WritePin(L6_G, L6_LED_Pin, GPIO_PIN_RESET);
			HAL_GPIO_WritePin(L7_G, L7_LED_Pin, GPIO_PIN_RESET);
			HAL_GPIO_WritePin(L8_G, L8_LED_Pin, GPIO_PIN_RESET);
		}
		if (color == OFF) {
			//éteint la LED
			HAL_GPIO_WritePin(C3_G, C3_LED_Pin, GPIO_PIN_RESET);
			HAL_GPIO_WritePin(L4_G, L4_LED_Pin, GPIO_PIN_RESET);
		}
		break;

	//LED1 de la ligne 5
	case P13:
		if (color == RED) {
			//changes les pins pour les colonne qu'on ne souhaite pas allumer en input
			LED_MODE(C2, C2_G, INMODE);
			LED_MODE(C3, C3_G, INMODE);

			//envoie la commande pour la LED qu'on veut allumer
			HAL_GPIO_WritePin(C1_G, C1_LED_Pin, GPIO_PIN_SET);
			HAL_GPIO_WritePin(L5_G, L5_LED_Pin, GPIO_PIN_RESET);

			//set tout les autre pin de ligne à 1 pour ne rien allumer en trop
			HAL_GPIO_WritePin(L1_G, L1_LED_Pin, GPIO_PIN_SET);
			HAL_GPIO_WritePin(L2_G, L2_LED_Pin, GPIO_PIN_SET);
			HAL_GPIO_WritePin(L3_G, L3_LED_Pin, GPIO_PIN_SET);
			HAL_GPIO_WritePin(L4_G, L4_LED_Pin, GPIO_PIN_SET);
			HAL_GPIO_WritePin(L6_G, L6_LED_Pin, GPIO_PIN_SET);
			HAL_GPIO_WritePin(L7_G, L7_LED_Pin, GPIO_PIN_SET);
			HAL_GPIO_WritePin(L8_G, L8_LED_Pin, GPIO_PIN_SET);
		}
		if (color == GRN) {
			//changes les pins pour les colonne qu'on ne souhaite pas allumer en input
			LED_MODE(C2, C2_G, INMODE);
			LED_MODE(C3, C3_G, INMODE);

			//envoie la commande pour la LED qu'on veut allumer
			HAL_GPIO_WritePin(C1_G, C1_LED_Pin, GPIO_PIN_RESET);
			HAL_GPIO_WritePin(L5_G, L5_LED_Pin, GPIO_PIN_SET);

			//set tout les autre pin de ligne à 1 pour ne rien allumer en trop
			HAL_GPIO_WritePin(L1_G, L1_LED_Pin, GPIO_PIN_RESET);
			HAL_GPIO_WritePin(L2_G, L2_LED_Pin, GPIO_PIN_RESET);
			HAL_GPIO_WritePin(L3_G, L3_LED_Pin, GPIO_PIN_RESET);
			HAL_GPIO_WritePin(L4_G, L4_LED_Pin, GPIO_PIN_RESET);
			HAL_GPIO_WritePin(L6_G, L6_LED_Pin, GPIO_PIN_RESET);
			HAL_GPIO_WritePin(L7_G, L7_LED_Pin, GPIO_PIN_RESET);
			HAL_GPIO_WritePin(L8_G, L8_LED_Pin, GPIO_PIN_RESET);
		}
		if (color == OFF) {
			//éteint la LED
			HAL_GPIO_WritePin(C1_G, C1_LED_Pin, GPIO_PIN_RESET);
			HAL_GPIO_WritePin(L5_G, L5_LED_Pin, GPIO_PIN_RESET);
		}
		break;

	//LED2 de la ligne 5
	case P14:
		if (color == RED) {
			//changes les pins pour les colonne qu'on ne souhaite pas allumer en input
			LED_MODE(C1, C1_G, INMODE);
			LED_MODE(C3, C3_G, INMODE);

			//envoie la commande pour la LED qu'on veut allumer
			HAL_GPIO_WritePin(C2_G, C2_LED_Pin, GPIO_PIN_SET);
			HAL_GPIO_WritePin(L5_G, L5_LED_Pin, GPIO_PIN_RESET);

			//set tout les autre pin de ligne à 1 pour ne rien allumer en trop
			HAL_GPIO_WritePin(L1_G, L1_LED_Pin, GPIO_PIN_SET);
			HAL_GPIO_WritePin(L2_G, L2_LED_Pin, GPIO_PIN_SET);
			HAL_GPIO_WritePin(L3_G, L3_LED_Pin, GPIO_PIN_SET);
			HAL_GPIO_WritePin(L4_G, L4_LED_Pin, GPIO_PIN_SET);
			HAL_GPIO_WritePin(L6_G, L6_LED_Pin, GPIO_PIN_SET);
			HAL_GPIO_WritePin(L7_G, L7_LED_Pin, GPIO_PIN_SET);
			HAL_GPIO_WritePin(L8_G, L8_LED_Pin, GPIO_PIN_SET);
		}
		if (color == GRN) {
			//changes les pins pour les colonne qu'on ne souhaite pas allumer en input
			LED_MODE(C1, C1_G, INMODE);
			LED_MODE(C3, C3_G, INMODE);

			//envoie la commande pour la LED qu'on veut allumer
			HAL_GPIO_WritePin(C2_G, C2_LED_Pin, GPIO_PIN_RESET);
			HAL_GPIO_WritePin(L5_G, L5_LED_Pin, GPIO_PIN_SET);

			//set tout les autre pin de ligne à 1 pour ne rien allumer en trop
			HAL_GPIO_WritePin(L1_G, L1_LED_Pin, GPIO_PIN_RESET);
			HAL_GPIO_WritePin(L2_G, L2_LED_Pin, GPIO_PIN_RESET);
			HAL_GPIO_WritePin(L3_G, L3_LED_Pin, GPIO_PIN_RESET);
			HAL_GPIO_WritePin(L4_G, L4_LED_Pin, GPIO_PIN_RESET);
			HAL_GPIO_WritePin(L6_G, L6_LED_Pin, GPIO_PIN_RESET);
			HAL_GPIO_WritePin(L7_G, L7_LED_Pin, GPIO_PIN_RESET);
			HAL_GPIO_WritePin(L8_G, L8_LED_Pin, GPIO_PIN_RESET);
		}
		if (color == OFF) {
			//éteint la LED
			HAL_GPIO_WritePin(C2_G, C2_LED_Pin, GPIO_PIN_RESET);
			HAL_GPIO_WritePin(L5_G, L5_LED_Pin, GPIO_PIN_RESET);
		}
		break;

	//LED3 de la ligne 5
	case P15:
		if (color == RED) {
			//changes les pins pour les colonne qu'on ne souhaite pas allumer en input
			LED_MODE(C1, C1_G, INMODE);
			LED_MODE(C2, C2_G, INMODE);

			//envoie la commande pour la LED qu'on veut allumer
			HAL_GPIO_WritePin(C3_G, C3_LED_Pin, GPIO_PIN_SET);
			HAL_GPIO_WritePin(L5_G, L5_LED_Pin, GPIO_PIN_RESET);

			//set tout les autre pin de ligne à 1 pour ne rien allumer en trop
			HAL_GPIO_WritePin(L1_G, L1_LED_Pin, GPIO_PIN_SET);
			HAL_GPIO_WritePin(L2_G, L2_LED_Pin, GPIO_PIN_SET);
			HAL_GPIO_WritePin(L3_G, L3_LED_Pin, GPIO_PIN_SET);
			HAL_GPIO_WritePin(L5_G, L4_LED_Pin, GPIO_PIN_SET);
			HAL_GPIO_WritePin(L6_G, L6_LED_Pin, GPIO_PIN_SET);
			HAL_GPIO_WritePin(L7_G, L7_LED_Pin, GPIO_PIN_SET);
			HAL_GPIO_WritePin(L8_G, L8_LED_Pin, GPIO_PIN_SET);
		}
		if (color == GRN) {
			//changes les pins pour les colonne qu'on ne souhaite pas allumer en input
			LED_MODE(C1, C1_G, INMODE);
			LED_MODE(C2, C2_G, INMODE);

			//envoie la commande pour la LED qu'on veut allumer
			HAL_GPIO_WritePin(C3_G, C3_LED_Pin, GPIO_PIN_RESET);
			HAL_GPIO_WritePin(L5_G, L5_LED_Pin, GPIO_PIN_SET);

			//set tout les autre pin de ligne à 1 pour ne rien allumer en trop
			HAL_GPIO_WritePin(L1_G, L1_LED_Pin, GPIO_PIN_RESET);
			HAL_GPIO_WritePin(L2_G, L2_LED_Pin, GPIO_PIN_RESET);
			HAL_GPIO_WritePin(L3_G, L3_LED_Pin, GPIO_PIN_RESET);
			HAL_GPIO_WritePin(L4_G, L4_LED_Pin, GPIO_PIN_RESET);
			HAL_GPIO_WritePin(L6_G, L6_LED_Pin, GPIO_PIN_RESET);
			HAL_GPIO_WritePin(L7_G, L7_LED_Pin, GPIO_PIN_RESET);
			HAL_GPIO_WritePin(L8_G, L8_LED_Pin, GPIO_PIN_RESET);
		}
		if (color == OFF) {
			//éteint la LED
			HAL_GPIO_WritePin(C3_G, C3_LED_Pin, GPIO_PIN_RESET);
			HAL_GPIO_WritePin(L5_G, L5_LED_Pin, GPIO_PIN_RESET);
		}
		break;
		//LED1 de la ligne 6
	case P16:
		if (color == RED) {
			//changes les pins pour les colonne qu'on ne souhaite pas allumer en input
			LED_MODE(C2, C2_G, INMODE);
			LED_MODE(C3, C3_G, INMODE);

			//envoie la commande pour la LED qu'on veut allumer
			HAL_GPIO_WritePin(C1_G, C1_LED_Pin, GPIO_PIN_SET);
			HAL_GPIO_WritePin(L6_G, L6_LED_Pin, GPIO_PIN_RESET);

			//set tout les autre pin de ligne à 1 pour ne rien allumer en trop
			HAL_GPIO_WritePin(L1_G, L1_LED_Pin, GPIO_PIN_SET);
			HAL_GPIO_WritePin(L3_G, L3_LED_Pin, GPIO_PIN_SET);
			HAL_GPIO_WritePin(L4_G, L4_LED_Pin, GPIO_PIN_SET);
			HAL_GPIO_WritePin(L5_G, L5_LED_Pin, GPIO_PIN_SET);
			HAL_GPIO_WritePin(L2_G, L2_LED_Pin, GPIO_PIN_SET);
			HAL_GPIO_WritePin(L7_G, L7_LED_Pin, GPIO_PIN_SET);
			HAL_GPIO_WritePin(L8_G, L8_LED_Pin, GPIO_PIN_SET);
		}
		if (color == GRN) {
			//changes les pins pour les colonne qu'on ne souhaite pas allumer en input
			LED_MODE(C2, C2_G, INMODE);
			LED_MODE(C3, C3_G, INMODE);

			//envoie la commande pour la LED qu'on veut allumer
			HAL_GPIO_WritePin(C1_G, C1_LED_Pin, GPIO_PIN_RESET);
			HAL_GPIO_WritePin(L6_G, L6_LED_Pin, GPIO_PIN_SET);

			//set tout les autre pin de ligne à 1 pour ne rien allumer en trop
			HAL_GPIO_WritePin(L1_G, L1_LED_Pin, GPIO_PIN_RESET);
			HAL_GPIO_WritePin(L3_G, L3_LED_Pin, GPIO_PIN_RESET);
			HAL_GPIO_WritePin(L4_G, L4_LED_Pin, GPIO_PIN_RESET);
			HAL_GPIO_WritePin(L5_G, L5_LED_Pin, GPIO_PIN_RESET);
			HAL_GPIO_WritePin(L2_G, L2_LED_Pin, GPIO_PIN_RESET);
			HAL_GPIO_WritePin(L7_G, L7_LED_Pin, GPIO_PIN_RESET);
			HAL_GPIO_WritePin(L8_G, L8_LED_Pin, GPIO_PIN_RESET);
		}
		if (color == OFF) {
			//éteint la LED
			HAL_GPIO_WritePin(C1_G, C1_LED_Pin, GPIO_PIN_RESET);
			HAL_GPIO_WritePin(L6_G, L6_LED_Pin, GPIO_PIN_RESET);
		}
		break;

	//LED2 de la ligne 6
	case P17:
		if (color == RED) {
			//changes les pins pour les colonne qu'on ne souhaite pas allumer en input
			LED_MODE(C1, C1_G, INMODE);
			LED_MODE(C3, C3_G, INMODE);

			//envoie la commande pour la LED qu'on veut allumer
			HAL_GPIO_WritePin(C2_G, C2_LED_Pin, GPIO_PIN_SET);
			HAL_GPIO_WritePin(L6_G, L6_LED_Pin, GPIO_PIN_RESET);

			//set tout les autre pin de ligne à 1 pour ne rien allumer en trop
			HAL_GPIO_WritePin(L1_G, L1_LED_Pin, GPIO_PIN_SET);
			HAL_GPIO_WritePin(L3_G, L3_LED_Pin, GPIO_PIN_SET);
			HAL_GPIO_WritePin(L4_G, L4_LED_Pin, GPIO_PIN_SET);
			HAL_GPIO_WritePin(L5_G, L5_LED_Pin, GPIO_PIN_SET);
			HAL_GPIO_WritePin(L2_G, L2_LED_Pin, GPIO_PIN_SET);
			HAL_GPIO_WritePin(L7_G, L7_LED_Pin, GPIO_PIN_SET);
			HAL_GPIO_WritePin(L8_G, L8_LED_Pin, GPIO_PIN_SET);
		}
		if (color == GRN) {
			//changes les pins pour les colonne qu'on ne souhaite pas allumer en input
			LED_MODE(C1, C1_G, INMODE);
			LED_MODE(C3, C3_G, INMODE);

			//envoie la commande pour la LED qu'on veut allumer
			HAL_GPIO_WritePin(C2_G, C2_LED_Pin, GPIO_PIN_RESET);
			HAL_GPIO_WritePin(L6_G, L6_LED_Pin, GPIO_PIN_SET);

			//set tout les autre pin de ligne à 1 pour ne rien allumer en trop
			HAL_GPIO_WritePin(L1_G, L1_LED_Pin, GPIO_PIN_RESET);
			HAL_GPIO_WritePin(L3_G, L3_LED_Pin, GPIO_PIN_RESET);
			HAL_GPIO_WritePin(L4_G, L4_LED_Pin, GPIO_PIN_RESET);
			HAL_GPIO_WritePin(L5_G, L5_LED_Pin, GPIO_PIN_RESET);
			HAL_GPIO_WritePin(L2_G, L2_LED_Pin, GPIO_PIN_RESET);
			HAL_GPIO_WritePin(L7_G, L7_LED_Pin, GPIO_PIN_RESET);
			HAL_GPIO_WritePin(L8_G, L8_LED_Pin, GPIO_PIN_RESET);
		}
		if (color == OFF) {
			//éteint la LED
			HAL_GPIO_WritePin(C2_G, C2_LED_Pin, GPIO_PIN_RESET);
			HAL_GPIO_WritePin(L6_G, L6_LED_Pin, GPIO_PIN_RESET);
		}
		break;

	//LED3 de la ligne 6
	case P18:
		if (color == RED) {
			//changes les pins pour les colonne qu'on ne souhaite pas allumer en input
			LED_MODE(C1, C1_G, INMODE);
			LED_MODE(C2, C2_G, INMODE);

			//envoie la commande pour la LED qu'on veut allumer
			HAL_GPIO_WritePin(C3_G, C3_LED_Pin, GPIO_PIN_SET);
			HAL_GPIO_WritePin(L6_G, L6_LED_Pin, GPIO_PIN_RESET);

			//set tout les autre pin de ligne à 1 pour ne rien allumer en trop
			HAL_GPIO_WritePin(L1_G, L1_LED_Pin, GPIO_PIN_SET);
			HAL_GPIO_WritePin(L3_G, L3_LED_Pin, GPIO_PIN_SET);
			HAL_GPIO_WritePin(L4_G, L4_LED_Pin, GPIO_PIN_SET);
			HAL_GPIO_WritePin(L5_G, L5_LED_Pin, GPIO_PIN_SET);
			HAL_GPIO_WritePin(L2_G, L2_LED_Pin, GPIO_PIN_SET);
			HAL_GPIO_WritePin(L7_G, L7_LED_Pin, GPIO_PIN_SET);
			HAL_GPIO_WritePin(L8_G, L8_LED_Pin, GPIO_PIN_SET);
		}
		if (color == GRN) {
			//changes les pins pour les colonne qu'on ne souhaite pas allumer en input
			LED_MODE(C1, C1_G, INMODE);
			LED_MODE(C2, C2_G, INMODE);

			//envoie la commande pour la LED qu'on veut allumer
			HAL_GPIO_WritePin(C3_G, C3_LED_Pin, GPIO_PIN_RESET);
			HAL_GPIO_WritePin(L6_G, L6_LED_Pin, GPIO_PIN_SET);

			//set tout les autre pin de ligne à 1 pour ne rien allumer en trop
			HAL_GPIO_WritePin(L1_G, L1_LED_Pin, GPIO_PIN_RESET);
			HAL_GPIO_WritePin(L3_G, L3_LED_Pin, GPIO_PIN_RESET);
			HAL_GPIO_WritePin(L4_G, L4_LED_Pin, GPIO_PIN_RESET);
			HAL_GPIO_WritePin(L5_G, L5_LED_Pin, GPIO_PIN_RESET);
			HAL_GPIO_WritePin(L2_G, L2_LED_Pin, GPIO_PIN_RESET);
			HAL_GPIO_WritePin(L7_G, L7_LED_Pin, GPIO_PIN_RESET);
			HAL_GPIO_WritePin(L8_G, L8_LED_Pin, GPIO_PIN_RESET);
		}
		if (color == OFF) {
			//éteint la LED
			HAL_GPIO_WritePin(C3_G, C3_LED_Pin, GPIO_PIN_RESET);
			HAL_GPIO_WritePin(L6_G, L6_LED_Pin, GPIO_PIN_RESET);
		}
		break;

		//LED1 de la ligne 7
	case P19:
		if (color == RED) {
			//changes les pins pour les colonne qu'on ne souhaite pas allumer en input
			LED_MODE(C2, C2_G, INMODE);
			LED_MODE(C3, C3_G, INMODE);

			//envoie la commande pour la LED qu'on veut allumer
			HAL_GPIO_WritePin(C1_G, C1_LED_Pin, GPIO_PIN_SET);
			HAL_GPIO_WritePin(L7_G, L7_LED_Pin, GPIO_PIN_RESET);

			//set tout les autre pin de ligne à 1 pour ne rien allumer en trop
			HAL_GPIO_WritePin(L1_G, L1_LED_Pin, GPIO_PIN_SET);
			HAL_GPIO_WritePin(L2_G, L2_LED_Pin, GPIO_PIN_SET);
			HAL_GPIO_WritePin(L4_G, L4_LED_Pin, GPIO_PIN_SET);
			HAL_GPIO_WritePin(L5_G, L5_LED_Pin, GPIO_PIN_SET);
			HAL_GPIO_WritePin(L6_G, L6_LED_Pin, GPIO_PIN_SET);
			HAL_GPIO_WritePin(L3_G, L3_LED_Pin, GPIO_PIN_SET);
			HAL_GPIO_WritePin(L8_G, L8_LED_Pin, GPIO_PIN_SET);
		}
		if (color == GRN) {
			//changes les pins pour les colonne qu'on ne souhaite pas allumer en input
			LED_MODE(C2, C2_G, INMODE);
			LED_MODE(C3, C3_G, INMODE);

			//envoie la commande pour la LED qu'on veut allumer
			HAL_GPIO_WritePin(C1_G, C1_LED_Pin, GPIO_PIN_RESET);
			HAL_GPIO_WritePin(L7_G, L7_LED_Pin, GPIO_PIN_SET);

			//set tout les autre pin de ligne à 1 pour ne rien allumer en trop
			HAL_GPIO_WritePin(L1_G, L1_LED_Pin, GPIO_PIN_RESET);
			HAL_GPIO_WritePin(L2_G, L2_LED_Pin, GPIO_PIN_RESET);
			HAL_GPIO_WritePin(L4_G, L4_LED_Pin, GPIO_PIN_RESET);
			HAL_GPIO_WritePin(L5_G, L5_LED_Pin, GPIO_PIN_RESET);
			HAL_GPIO_WritePin(L6_G, L6_LED_Pin, GPIO_PIN_RESET);
			HAL_GPIO_WritePin(L3_G, L3_LED_Pin, GPIO_PIN_RESET);
			HAL_GPIO_WritePin(L8_G, L8_LED_Pin, GPIO_PIN_RESET);
		}
		if (color == OFF) {
			//éteint la LED
			HAL_GPIO_WritePin(C1_G, C1_LED_Pin, GPIO_PIN_RESET);
			HAL_GPIO_WritePin(L7_G, L7_LED_Pin, GPIO_PIN_RESET);
		}
		break;

	//LED2 de la ligne 7
	case P20:
		if (color == RED) {
			//changes les pins pour les colonne qu'on ne souhaite pas allumer en input
			LED_MODE(C1, C1_G, INMODE);
			LED_MODE(C3, C3_G, INMODE);

			//envoie la commande pour la LED qu'on veut allumer
			HAL_GPIO_WritePin(C2_G, C2_LED_Pin, GPIO_PIN_SET);
			HAL_GPIO_WritePin(L7_G, L7_LED_Pin, GPIO_PIN_RESET);

			//set tout les autre pin de ligne à 1 pour ne rien allumer en trop
			HAL_GPIO_WritePin(L1_G, L1_LED_Pin, GPIO_PIN_SET);
			HAL_GPIO_WritePin(L2_G, L2_LED_Pin, GPIO_PIN_SET);
			HAL_GPIO_WritePin(L4_G, L4_LED_Pin, GPIO_PIN_SET);
			HAL_GPIO_WritePin(L5_G, L5_LED_Pin, GPIO_PIN_SET);
			HAL_GPIO_WritePin(L6_G, L6_LED_Pin, GPIO_PIN_SET);
			HAL_GPIO_WritePin(L3_G, L3_LED_Pin, GPIO_PIN_SET);
			HAL_GPIO_WritePin(L8_G, L8_LED_Pin, GPIO_PIN_SET);
		}
		if (color == GRN) {
			//changes les pins pour les colonne qu'on ne souhaite pas allumer en input
			LED_MODE(C1, C1_G, INMODE);
			LED_MODE(C3, C3_G, INMODE);

			//envoie la commande pour la LED qu'on veut allumer
			HAL_GPIO_WritePin(C2_G, C2_LED_Pin, GPIO_PIN_RESET);
			HAL_GPIO_WritePin(L7_G, L7_LED_Pin, GPIO_PIN_SET);

			//set tout les autre pin de ligne à 1 pour ne rien allumer en trop
			HAL_GPIO_WritePin(L1_G, L1_LED_Pin, GPIO_PIN_RESET);
			HAL_GPIO_WritePin(L2_G, L2_LED_Pin, GPIO_PIN_RESET);
			HAL_GPIO_WritePin(L4_G, L4_LED_Pin, GPIO_PIN_RESET);
			HAL_GPIO_WritePin(L5_G, L5_LED_Pin, GPIO_PIN_RESET);
			HAL_GPIO_WritePin(L6_G, L6_LED_Pin, GPIO_PIN_RESET);
			HAL_GPIO_WritePin(L3_G, L3_LED_Pin, GPIO_PIN_RESET);
			HAL_GPIO_WritePin(L8_G, L8_LED_Pin, GPIO_PIN_RESET);
		}
		if (color == OFF) {
			//éteint la LED
			HAL_GPIO_WritePin(C2_G, C2_LED_Pin, GPIO_PIN_RESET);
			HAL_GPIO_WritePin(L7_G, L7_LED_Pin, GPIO_PIN_RESET);
		}
		break;

	//LED3 de la ligne 7
	case P21:
		if (color == RED) {
			//changes les pins pour les colonne qu'on ne souhaite pas allumer en input
			LED_MODE(C1, C1_G, INMODE);
			LED_MODE(C2, C2_G, INMODE);

			//envoie la commande pour la LED qu'on veut allumer
			HAL_GPIO_WritePin(C3_G, C3_LED_Pin, GPIO_PIN_SET);
			HAL_GPIO_WritePin(L7_G, L7_LED_Pin, GPIO_PIN_RESET);

			//set tout les autre pin de ligne à 1 pour ne rien allumer en trop
			HAL_GPIO_WritePin(L1_G, L1_LED_Pin, GPIO_PIN_SET);
			HAL_GPIO_WritePin(L2_G, L2_LED_Pin, GPIO_PIN_SET);
			HAL_GPIO_WritePin(L4_G, L4_LED_Pin, GPIO_PIN_SET);
			HAL_GPIO_WritePin(L5_G, L5_LED_Pin, GPIO_PIN_SET);
			HAL_GPIO_WritePin(L6_G, L6_LED_Pin, GPIO_PIN_SET);
			HAL_GPIO_WritePin(L3_G, L3_LED_Pin, GPIO_PIN_SET);
			HAL_GPIO_WritePin(L8_G, L8_LED_Pin, GPIO_PIN_SET);
		}
		if (color == GRN) {
			//changes les pins pour les colonne qu'on ne souhaite pas allumer en input
			LED_MODE(C1, C1_G, INMODE);
			LED_MODE(C2, C2_G, INMODE);

			//envoie la commande pour la LED qu'on veut allumer
			HAL_GPIO_WritePin(C3_G, C3_LED_Pin, GPIO_PIN_RESET);
			HAL_GPIO_WritePin(L7_G, L7_LED_Pin, GPIO_PIN_SET);

			//set tout les autre pin de ligne à 1 pour ne rien allumer en trop
			HAL_GPIO_WritePin(L1_G, L1_LED_Pin, GPIO_PIN_RESET);
			HAL_GPIO_WritePin(L2_G, L2_LED_Pin, GPIO_PIN_RESET);
			HAL_GPIO_WritePin(L4_G, L4_LED_Pin, GPIO_PIN_RESET);
			HAL_GPIO_WritePin(L5_G, L5_LED_Pin, GPIO_PIN_RESET);
			HAL_GPIO_WritePin(L6_G, L6_LED_Pin, GPIO_PIN_RESET);
			HAL_GPIO_WritePin(L3_G, L3_LED_Pin, GPIO_PIN_RESET);
			HAL_GPIO_WritePin(L8_G, L8_LED_Pin, GPIO_PIN_RESET);
		}
		if (color == OFF) {
			//éteint la LED
			HAL_GPIO_WritePin(C3_G, C3_LED_Pin, GPIO_PIN_RESET);
			HAL_GPIO_WritePin(L7_G, L7_LED_Pin, GPIO_PIN_RESET);
		}
		break;

		//LED1 de la ligne 8
	case P22:
		if (color == RED) {
			//changes les pins pour les colonne qu'on ne souhaite pas allumer en input
			LED_MODE(C2, C2_G, INMODE);
			LED_MODE(C3, C3_G, INMODE);

			//envoie la commande pour la LED qu'on veut allumer
			HAL_GPIO_WritePin(C1_G, C1_LED_Pin, GPIO_PIN_SET);
			HAL_GPIO_WritePin(L8_G, L8_LED_Pin, GPIO_PIN_RESET);

			//set tout les autre pin de ligne à 1 pour ne rien allumer en trop
			HAL_GPIO_WritePin(L1_G, L1_LED_Pin, GPIO_PIN_SET);
			HAL_GPIO_WritePin(L2_G, L2_LED_Pin, GPIO_PIN_SET);
			HAL_GPIO_WritePin(L4_G, L4_LED_Pin, GPIO_PIN_SET);
			HAL_GPIO_WritePin(L5_G, L5_LED_Pin, GPIO_PIN_SET);
			HAL_GPIO_WritePin(L6_G, L6_LED_Pin, GPIO_PIN_SET);
			HAL_GPIO_WritePin(L7_G, L7_LED_Pin, GPIO_PIN_SET);
			HAL_GPIO_WritePin(L3_G, L3_LED_Pin, GPIO_PIN_SET);
		}
		if (color == GRN) {
			//changes les pins pour les colonne qu'on ne souhaite pas allumer en input
			LED_MODE(C2, C2_G, INMODE);
			LED_MODE(C3, C3_G, INMODE);

			//envoie la commande pour la LED qu'on veut allumer
			HAL_GPIO_WritePin(C1_G, C1_LED_Pin, GPIO_PIN_RESET);
			HAL_GPIO_WritePin(L8_G, L8_LED_Pin, GPIO_PIN_SET);

			//set tout les autre pin de ligne à 1 pour ne rien allumer en trop
			HAL_GPIO_WritePin(L1_G, L1_LED_Pin, GPIO_PIN_RESET);
			HAL_GPIO_WritePin(L2_G, L2_LED_Pin, GPIO_PIN_RESET);
			HAL_GPIO_WritePin(L4_G, L4_LED_Pin, GPIO_PIN_RESET);
			HAL_GPIO_WritePin(L5_G, L5_LED_Pin, GPIO_PIN_RESET);
			HAL_GPIO_WritePin(L6_G, L6_LED_Pin, GPIO_PIN_RESET);
			HAL_GPIO_WritePin(L7_G, L7_LED_Pin, GPIO_PIN_RESET);
			HAL_GPIO_WritePin(L3_G, L3_LED_Pin, GPIO_PIN_RESET);
		}
		if (color == OFF) {
			//éteint la LED
			HAL_GPIO_WritePin(C1_G, C1_LED_Pin, GPIO_PIN_RESET);
			HAL_GPIO_WritePin(L8_G, L8_LED_Pin, GPIO_PIN_RESET);
		}
		break;

	//LED2 de la ligne 8
	case P23:
		if (color == RED) {
			//changes les pins pour les colonne qu'on ne souhaite pas allumer en input
			LED_MODE(C1, C1_G, INMODE);
			LED_MODE(C3, C3_G, INMODE);

			//envoie la commande pour la LED qu'on veut allumer
			HAL_GPIO_WritePin(C2_G, C2_LED_Pin, GPIO_PIN_SET);
			HAL_GPIO_WritePin(L8_G, L8_LED_Pin, GPIO_PIN_RESET);

			//set tout les autre pin de ligne à 1 pour ne rien allumer en trop
			HAL_GPIO_WritePin(L1_G, L1_LED_Pin, GPIO_PIN_SET);
			HAL_GPIO_WritePin(L2_G, L2_LED_Pin, GPIO_PIN_SET);
			HAL_GPIO_WritePin(L4_G, L4_LED_Pin, GPIO_PIN_SET);
			HAL_GPIO_WritePin(L5_G, L5_LED_Pin, GPIO_PIN_SET);
			HAL_GPIO_WritePin(L6_G, L6_LED_Pin, GPIO_PIN_SET);
			HAL_GPIO_WritePin(L7_G, L7_LED_Pin, GPIO_PIN_SET);
			HAL_GPIO_WritePin(L3_G, L3_LED_Pin, GPIO_PIN_SET);
		}
		if (color == GRN) {
			//changes les pins pour les colonne qu'on ne souhaite pas allumer en input
			LED_MODE(C1, C1_G, INMODE);
			LED_MODE(C3, C3_G, INMODE);

			//envoie la commande pour la LED qu'on veut allumer
			HAL_GPIO_WritePin(C2_G, C2_LED_Pin, GPIO_PIN_RESET);
			HAL_GPIO_WritePin(L8_G, L8_LED_Pin, GPIO_PIN_SET);

			//set tout les autre pin de ligne à 1 pour ne rien allumer en trop
			HAL_GPIO_WritePin(L1_G, L1_LED_Pin, GPIO_PIN_RESET);
			HAL_GPIO_WritePin(L2_G, L2_LED_Pin, GPIO_PIN_RESET);
			HAL_GPIO_WritePin(L4_G, L4_LED_Pin, GPIO_PIN_RESET);
			HAL_GPIO_WritePin(L5_G, L5_LED_Pin, GPIO_PIN_RESET);
			HAL_GPIO_WritePin(L6_G, L6_LED_Pin, GPIO_PIN_RESET);
			HAL_GPIO_WritePin(L7_G, L7_LED_Pin, GPIO_PIN_RESET);
			HAL_GPIO_WritePin(L3_G, L3_LED_Pin, GPIO_PIN_RESET);
		}
		if (color == OFF) {
			//éteint la LED
			HAL_GPIO_WritePin(C2_G, C2_LED_Pin, GPIO_PIN_RESET);
			HAL_GPIO_WritePin(L8_G, L8_LED_Pin, GPIO_PIN_RESET);
		}
		break;

	//LED3 de la ligne 8
	case P24:
		if (color == RED) {
			//changes les pins pour les colonne qu'on ne souhaite pas allumer en input
			LED_MODE(C1, C1_G, INMODE);
			LED_MODE(C2, C2_G, INMODE);

			//envoie la commande pour la LED qu'on veut allumer
			HAL_GPIO_WritePin(C3_G, C3_LED_Pin, GPIO_PIN_SET);
			HAL_GPIO_WritePin(L8_G, L8_LED_Pin, GPIO_PIN_RESET);

			//set tout les autre pin de ligne à 1 pour ne rien allumer en trop
			HAL_GPIO_WritePin(L1_G, L1_LED_Pin, GPIO_PIN_SET);
			HAL_GPIO_WritePin(L2_G, L2_LED_Pin, GPIO_PIN_SET);
			HAL_GPIO_WritePin(L4_G, L4_LED_Pin, GPIO_PIN_SET);
			HAL_GPIO_WritePin(L5_G, L5_LED_Pin, GPIO_PIN_SET);
			HAL_GPIO_WritePin(L6_G, L6_LED_Pin, GPIO_PIN_SET);
			HAL_GPIO_WritePin(L7_G, L7_LED_Pin, GPIO_PIN_SET);
			HAL_GPIO_WritePin(L3_G, L3_LED_Pin, GPIO_PIN_SET);
		}
		if (color == GRN) {
			//changes les pins pour les colonne qu'on ne souhaite pas allumer en input
			LED_MODE(C1, C1_G, INMODE);
			LED_MODE(C2, C2_G, INMODE);

			//envoie la commande pour la LED qu'on veut allumer
			HAL_GPIO_WritePin(C3_G, C3_LED_Pin, GPIO_PIN_RESET);
			HAL_GPIO_WritePin(L8_G, L8_LED_Pin, GPIO_PIN_SET);

			//set tout les autre pin de ligne à 1 pour ne rien allumer en trop
			HAL_GPIO_WritePin(L1_G, L1_LED_Pin, GPIO_PIN_RESET);
			HAL_GPIO_WritePin(L2_G, L2_LED_Pin, GPIO_PIN_RESET);
			HAL_GPIO_WritePin(L4_G, L4_LED_Pin, GPIO_PIN_RESET);
			HAL_GPIO_WritePin(L5_G, L5_LED_Pin, GPIO_PIN_RESET);
			HAL_GPIO_WritePin(L6_G, L6_LED_Pin, GPIO_PIN_RESET);
			HAL_GPIO_WritePin(L7_G, L7_LED_Pin, GPIO_PIN_RESET);
			HAL_GPIO_WritePin(L3_G, L3_LED_Pin, GPIO_PIN_RESET);
		}
		if (color == OFF) {
			//éteint la LED
			HAL_GPIO_WritePin(C3_G, C3_LED_Pin, GPIO_PIN_RESET);
			HAL_GPIO_WritePin(L8_G, L8_LED_Pin, GPIO_PIN_RESET);
		}
		break;
	}
	LED_OFF();
}
//fonction qui gère les LEDs avec un teableau
void LED_Field(uint8_t array[13])
{
	for(int i = 1; i < 13; i++)
	{
		//if it's OFF
		if(array[i] != 0){
		//regarde la valeur de la case pour savoir si il faut l'allumer, l'éteindre...
		LEDP(i,array[i]);
		}
	}
}

//fonction pour éteindre toutes les LEDs
void LED_OFF(void) {
	HAL_Delay(1);

	//change toutes les pins de colonne en sortie
	LED_MODE(C1, C1_G, OUTMODE);
	LED_MODE(C2, C2_G, OUTMODE);
	LED_MODE(C3, C3_G, OUTMODE);

	//envoie la commande pour la LED qu'on veut allumer
	HAL_GPIO_WritePin(C1_G, C1_LED_Pin, GPIO_PIN_SET);
	HAL_GPIO_WritePin(C2_G, C2_LED_Pin, GPIO_PIN_SET);
	HAL_GPIO_WritePin(C3_G, C3_LED_Pin, GPIO_PIN_SET);

	//set tout les autre pin de ligne à 1 pour ne rien allumer en trop
	HAL_GPIO_WritePin(L1_G, L1_LED_Pin, GPIO_PIN_SET);
	HAL_GPIO_WritePin(L2_G, L2_LED_Pin, GPIO_PIN_SET);
	HAL_GPIO_WritePin(L3_G, L3_LED_Pin, GPIO_PIN_SET);
	HAL_GPIO_WritePin(L4_G, L4_LED_Pin, GPIO_PIN_SET);

}
//change le registre pour modifié la PIN en in/output pour faire fonctionner la matrice
void LED_MODE(char pin, GPIO_TypeDef *group, char mode) {
	if (mode == OUTMODE) {
		group->MODER |= (0x1 << (pin * 2));
	}
	if (mode == INMODE) {
		group->MODER &= ~(0x3 << (pin * 2));
	}
}

/* USER CODE END 4 */

void Error_Handler(void)
{
  __disable_irq();
  while (1)
  {
  }
}
